# R7FA4W1AD register map
Vendor: Renesas; Series: RA4; File version: 1.0
CPU: CM4 r0p1, little endian, MPU, FPU, VTOR, 4 interrupt priority bits
Registers are 8-bit, read-write, reset 0x0 unless marked. A register's access mark holds for its fields unless they carry their own. Offsets are from the block's base; [hi:lo] are bit positions.

## MSTP — Module Stop Control B,C,D
Base 0x40047000
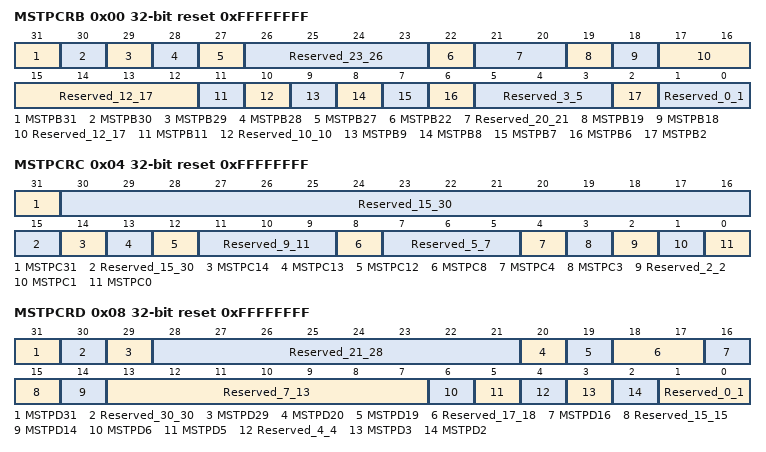
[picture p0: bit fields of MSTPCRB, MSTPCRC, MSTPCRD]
0x00 MSTPCRB 32-bit reset 0xFFFFFFFF — Module Stop Control Register B
  [31] MSTPB31 — Serial Communication Interface 0 Module Stop
  [30] MSTPB30 — Serial Communication Interface 1 Module Stop
  [29] MSTPB29 — Serial Communication Interface 2 Module Stop
  [28] MSTPB28 — Serial Communication Interface 3 Module Stop
  [27] MSTPB27 — Serial Communication Interface 4 Module Stop
  [26:23] Reserved_23_26 — These bits are read as 1111. The write value should be 1111.
  [22] MSTPB22 — Serial Communication Interface 9 Module Stop
  [21:20] Reserved_20_21 — These bits are read as 11. The write value should be 11.
  [19] MSTPB19 — Serial Peripheral Interface 0 Module Stop
  [18] MSTPB18 — Serial Peripheral Interface 1 Module Stop
  [17:12] Reserved_12_17 — These bits are read as 111111. The write value should be 111111.
  [11] MSTPB11 — Universal Serial Bus 2.0 FS Interface Module Stop
  [10] Reserved_10_10 — This bit is read as 1. The write value should be 1.
  [9] MSTPB9 — I2C Bus Interface 0 Module Stop
  [8] MSTPB8 — I2C Bus Interface 1 Module Stop
  [7] MSTPB7 — I2C Bus Interface 2 Module Stop
  [6] MSTPB6 — Queued Serial Peripheral Interface Module Stop
  [5:3] Reserved_3_5 — These bits are read as 111. The write value should be 111.
  [2] MSTPB2 — Controller Area Network Module Stop
  [1:0] Reserved_0_1 — These bits are read as 11. The write value should be 11.
0x04 MSTPCRC 32-bit reset 0xFFFFFFFF — Module Stop Control Register C
  [31] MSTPC31 — TSIP Module Stop
  [30:15] Reserved_15_30 — These bits are read as 1111111111111111. The write value should be 1111111111111111.
  [14] MSTPC14 — Event Link Controller Module Stop
  [13] MSTPC13 — Data Operation Circuit Module Stop
  [12] MSTPC12 — Secure Digital Host Interface/Multi Media Card Interface ModuleStop
  [11:9] Reserved_9_11 — These bits are read as 111. The write value should be 111.
  [8] MSTPC8 — Synchronous Serial Interface 0 Module Stop
  [7:5] Reserved_5_7 — These bits are read as 111. The write value should be 111.
  [4] MSTPC4 — Segment LCD Controller Module Stop
  [3] MSTPC3 — Capacitive Touch Sensing Unit Module Stop
  [2] Reserved_2_2 — This bit is read as 1. The write value should be 1.
  [1] MSTPC1 — Cyclic Redundancy Check Calculator Module Stop
  [0] MSTPC0 — Clock Frequency Accuracy Measurement Circuit Module Stop
0x08 MSTPCRD 32-bit reset 0xFFFFFFFF — Module Stop Control Register D
  [31] MSTPD31 — Operational Amplifier Module Stop
  [30] Reserved_30_30 — This bit is read as 1. The write value should be 1.
  [29] MSTPD29 — Low,Power Analog Comparator Module Stop
  [28:21] Reserved_21_28 — These bits are read as 11111111. The write value should be 11111111.
  [20] MSTPD20 — 12-Bit D/A Converter Module Stop
  [19] MSTPD19 — 8-bit D/A Converter Module Stop
  [18:17] Reserved_17_18 — These bits are read as 11. The write value should be 11.
  [16] MSTPD16 — 14-Bit A/D Converter Module Stop
  [15] Reserved_15_15 — This bit is read as 1. The write value should be 1.
  [14] MSTPD14 — Port Output Enable for GPT Module Stop
  [13:7] Reserved_7_13 — These bits are read as 1111111. The write value should be 1111111.
  [6] MSTPD6 — General PWM Timer 169 to 164 Module Stop
  [5] MSTPD5 — General PWM Timer 323 to 320 Module Stop
  [4] Reserved_4_4 — This bit is read as 1. The write value should be 1.
  [3] MSTPD3 — Asynchronous General Purpose Timer 0 Module Stop
  [2] MSTPD2 — Asynchronous General Purpose Timer 1 Module Stop
  [1:0] Reserved_0_1 — These bits are read as 11. The write value should be 11.

## FCACHE — Flash Cache
Base 0x4001C000
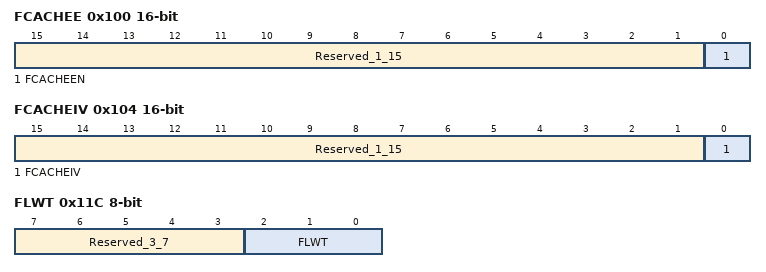
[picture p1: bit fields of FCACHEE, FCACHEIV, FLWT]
0x100 FCACHEE 16-bit — Flash Cache Enable Register
  [15:1] Reserved_1_15 — These bits are read as 000000000000000. The write value should be 000000000000000.
  [0] FCACHEEN — FCACHE Enable
0x104 FCACHEIV 16-bit — Flash Cache Invalidate Register
  [15:1] Reserved_1_15 — These bits are read as 000000000000000. The write value should be 000000000000000.
  [0] FCACHEIV write-1-sets read-modifies — FCACHE Invalidation
0x11C FLWT — Flash Wait Cycle Register
  [7:3] Reserved_3_7 — These bits are read as 00000. The write value should be 00000.
  [2:0] FLWT — These bits represent the ratio of the CPU clock period to the Flash memory access time.
